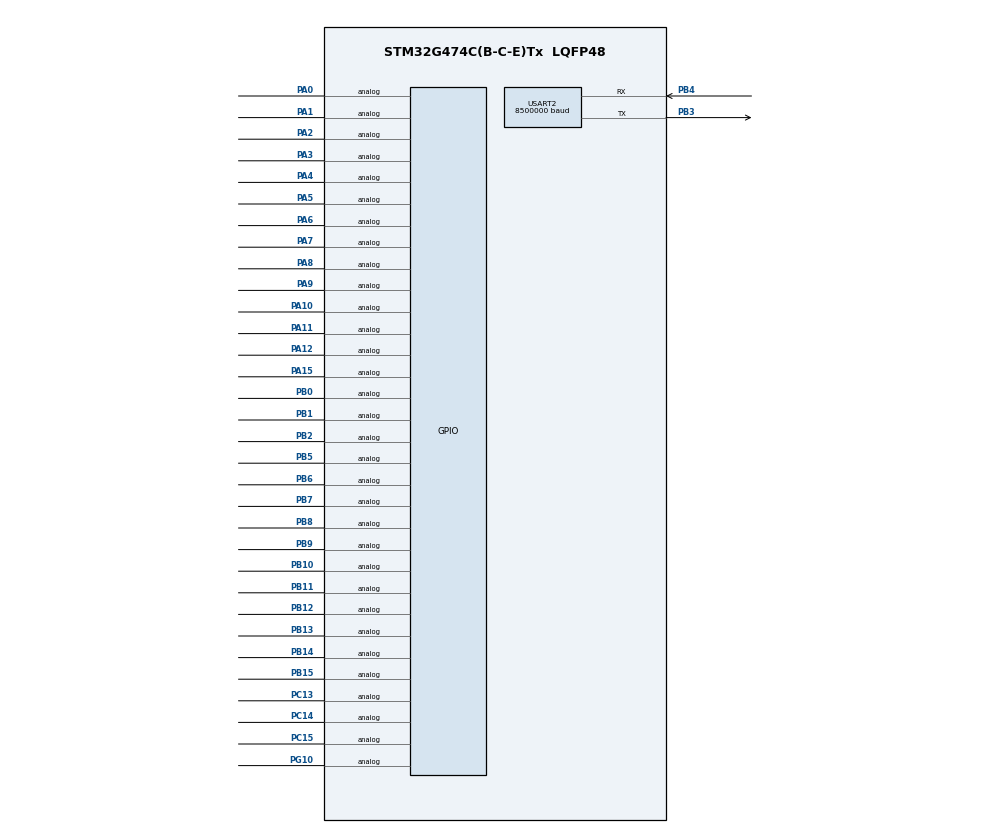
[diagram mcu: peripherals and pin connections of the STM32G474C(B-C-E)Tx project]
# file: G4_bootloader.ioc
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Mcu.Family=STM32G4
Mcu.Name=STM32G474C(B-C-E)Tx
Mcu.Package=LQFP48
NVIC.PriorityGroup=NVIC_PRIORITYGROUP_4
NVIC.USART2_IRQn=true\:0\:0\:false\:false\:true\:true\:true\:true
PA0.Signal=GPIO_Analog
PA1.Signal=GPIO_Analog
PA10.Signal=GPIO_Analog
PA11.Signal=GPIO_Analog
PA12.Signal=GPIO_Analog
PA13.Mode=Serial_Wire
PA13.Signal=SYS_JTMS-SWDIO
PA14.Mode=Serial_Wire
PA14.Signal=SYS_JTCK-SWCLK
PA15.Signal=GPIO_Analog
PA2.Signal=GPIO_Analog
PA3.Signal=GPIO_Analog
PA4.Signal=GPIO_Analog
PA5.Signal=GPIO_Analog
PA6.Signal=GPIO_Analog
PA7.Signal=GPIO_Analog
PA8.Signal=GPIO_Analog
PA9.Signal=GPIO_Analog
PB0.Signal=GPIO_Analog
PB1.Signal=GPIO_Analog
PB10.Signal=GPIO_Analog
PB11.Signal=GPIO_Analog
PB12.Signal=GPIO_Analog
PB13.Signal=GPIO_Analog
PB14.Signal=GPIO_Analog
PB15.Signal=GPIO_Analog
PB2.Signal=GPIO_Analog
PB3.GPIO_ModeDefaultOD=GPIO_MODE_AF_PP
PB3.GPIO_Speed=GPIO_SPEED_FREQ_MEDIUM
PB3.Mode=Multiprocessor_communication
PB3.Signal=USART2_TX
PB4.GPIO_ModeDefaultOD=GPIO_MODE_AF_PP
PB4.GPIO_Speed=GPIO_SPEED_FREQ_HIGH
PB4.Mode=Multiprocessor_communication
PB4.Signal=USART2_RX
PB5.Signal=GPIO_Analog
PB6.Signal=GPIO_Analog
PB7.Signal=GPIO_Analog
PB8-BOOT0.Signal=GPIO_Analog
PB9.Signal=GPIO_Analog
PC13.Signal=GPIO_Analog
PC14-OSC32_IN.Signal=GPIO_Analog
PC15-OSC32_OUT.Signal=GPIO_Analog
PF0-OSC_IN.Mode=HSE-External-Oscillator
PF0-OSC_IN.Signal=RCC_OSC_IN
PF1-OSC_OUT.Mode=HSE-External-Oscillator
PF1-OSC_OUT.Signal=RCC_OSC_OUT
PG10-NRST.Signal=GPIO_Analog
ProjectManager.HeapSize=0x200
ProjectManager.StackSize=0x400
ProjectManager.TargetToolchain=CMake
RCC.ADC12Freq_Value=136000000
RCC.ADC345Freq_Value=136000000
RCC.AHBFreq_Value=136000000
RCC.APB1Freq_Value=136000000
RCC.APB1TimFreq_Value=136000000
RCC.APB2Freq_Value=136000000
RCC.APB2TimFreq_Value=136000000
RCC.CK48CLockSelection=RCC_USBCLKSOURCE_HSI48
RCC.CortexFreq_Value=136000000
RCC.EXTERNAL_CLOCK_VALUE=12288000
RCC.HCLKFreq_Value=136000000
RCC.HSE_VALUE=8000000
RCC.HSI48_VALUE=48000000
RCC.HSI_VALUE=16000000
RCC.LSE_VALUE=32768
RCC.PLLM=RCC_PLLM_DIV2
RCC.PLLN=68
RCC.PLLSourceVirtual=RCC_PLLSOURCE_HSE
RCC.PWR_Regulator_Voltage_Scale=PWR_REGULATOR_VOLTAGE_SCALE1_BOOST
RCC.SYSCLKFreq_VALUE=136000000
RCC.SYSCLKSource=RCC_SYSCLKSOURCE_PLLCLK
RCC.USBFreq_Value=48000000
RCC.VCOOutputFreq_Value=272000000
USART2.Address=59
USART2.AddressLength=UART_ADDRESS_DETECT_7B
USART2.BaudRate=8500000
USART2.OverSampling=UART_OVERSAMPLING_8
USART2.VirtualMode-Multiprocessor_communication=VM_ASYNC
USART2.WakeUpMethod=UART_WAKEUPMETHOD_ADDRESSMARK
USART2.WordLength=WORDLENGTH_9B
VP_SYS_VS_DBSignals.Mode=DisableDeadBatterySignals
VP_TIM1_VS_ClockSourceINT.Mode=Internal
board=custom

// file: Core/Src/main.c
/* USER CODE BEGIN Header */
/**
  ******************************************************************************
  * @file           : main.c
  * @brief          : Main program body
  ******************************************************************************
  * @attention
  *
  * Copyright (c) 2026 STMicroelectronics.
  * All rights reserved.
  *
  * This software is licensed under terms that can be found in the LICENSE file
  * in the root directory of this software component.
  * If no LICENSE file comes with this software, it is provided AS-IS.
  *
  ******************************************************************************
  */
/* USER CODE END Header */
#include "main.h"
#include "tim.h"
#include "usart.h"
#include "gpio.h"

void SystemClock_Config(void);

/* USER CODE BEGIN 0 */
// #include "stm32g4xx_hal.h"
/* USER CODE END 0 */

int main(void)
{

  /* MCU Configuration--------------------------------------------------------*/

  /* Reset of all peripherals, Initializes the Flash interface and the Systick. */
  HAL_Init();

  /* Configure the system clock */
  SystemClock_Config();

  /* Initialize all configured peripherals */
  MX_GPIO_Init();
  MX_USART2_UART_Init();
  MX_TIM1_Init();
  /* USER CODE BEGIN 2 */

  // MX_TIM1_Init(); < чисто, чтобы HAL включился
  g4_bootloader();

  /* USER CODE END 2 */

  /* Infinite loop */
  while (1)
  {

  }
}

void SystemClock_Config(void)
{
  LL_FLASH_SetLatency(LL_FLASH_LATENCY_3);
  while(LL_FLASH_GetLatency() != LL_FLASH_LATENCY_3)
  {
  }
  LL_PWR_EnableRange1BoostMode();
  LL_RCC_HSE_Enable();
   /* Wait till HSE is ready */
  while(LL_RCC_HSE_IsReady() != 1)
  {
  }

  LL_RCC_PLL_ConfigDomain_SYS(LL_RCC_PLLSOURCE_HSE, LL_RCC_PLLM_DIV_2, 68, LL_RCC_PLLR_DIV_2);
  LL_RCC_PLL_EnableDomain_SYS();
  LL_RCC_PLL_Enable();
   /* Wait till PLL is ready */
  while(LL_RCC_PLL_IsReady() != 1)
  {
  }

  LL_RCC_SetSysClkSource(LL_RCC_SYS_CLKSOURCE_PLL);
  LL_RCC_SetAHBPrescaler(LL_RCC_SYSCLK_DIV_2);
   /* Wait till System clock is ready */
  while(LL_RCC_GetSysClkSource() != LL_RCC_SYS_CLKSOURCE_STATUS_PLL)
  {
  }

  /* Insure 1us transition state at intermediate medium speed clock*/
  for (__IO uint32_t i = (170 >> 1); i !=0; i--);

  /* Set AHB prescaler*/
  LL_RCC_SetAHBPrescaler(LL_RCC_SYSCLK_DIV_1);
  LL_RCC_SetAPB1Prescaler(LL_RCC_APB1_DIV_1);
  LL_RCC_SetAPB2Prescaler(LL_RCC_APB2_DIV_1);
  LL_SetSystemCoreClock(136000000);

   /* Update the time base */
  if (HAL_InitTick (TICK_INT_PRIORITY) != HAL_OK)
  {
    Error_Handler();
  }
}

void Error_Handler(void)
{
  __disable_irq();
  while (1)
  {
  }
}
